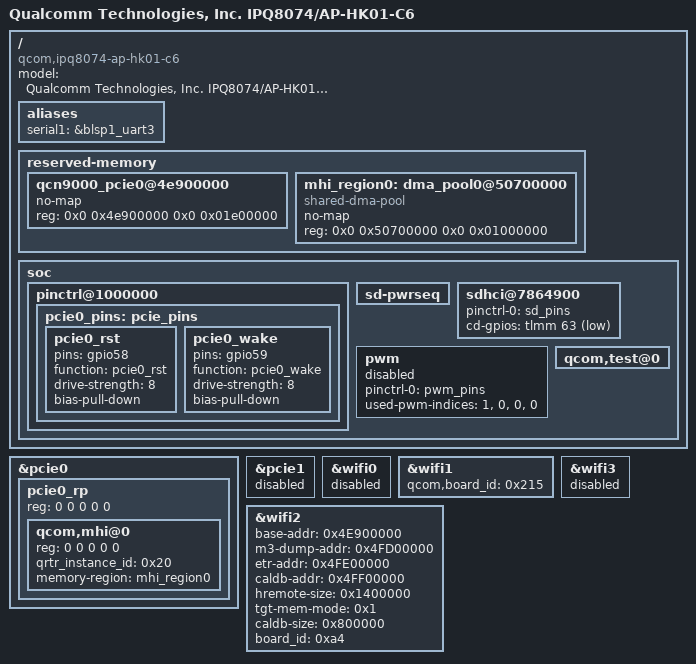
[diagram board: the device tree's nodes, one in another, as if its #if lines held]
// SPDX-License-Identifier: GPL-2.0-only
/dts-v1/;
/* Copyright (c) 2017, 2020, The Linux Foundation. All rights reserved.
 */
#include "ipq8074-hk01.dtsi"

/ {
	model = "Qualcomm Technologies, Inc. IPQ8074/AP-HK01-C6";
	compatible = "qcom,ipq8074-ap-hk01-c6", "qcom,ipq8074-hk01", "qcom,ipq8074";

	aliases {
		serial1 = &blsp1_uart3;
	};

	reserved-memory {
/* No Pine attach in 256M profile */
#if !defined(__IPQ_MEM_PROFILE_256_MB__)
#ifdef __IPQ_MEM_PROFILE_512_MB__
	/*                      512 MB Profile
	 * +========+==============+=========================+
	 * | Region | Start Offset |          Size           |
	 * +--------+--------------+-------------------------+
	 * |  NSS   |  0x40000000  |          16MB           |
	 * +--------+--------------+-------------------------+
	 * |        |              |                         |
	 * | Linux  |  0x41000000  | Depends on total memory |
	 * |        |              |                         |
	 * +--------+--------------+-------------------------+
	 * | TZ APP |  0x4A400000  |           1MB           |
	 * +--------+--------------+-------------------------+
	 * | uboot  |  0x4A600000  |           4MB           |
	 * +--------+--------------+-------------------------+
	 * |  SBL   |  0x4AA00000  |           1MB           |
	 * +--------+--------------+-------------------------+
	 * |  smem  |  0x4AB00000  |           1MB           |
	 * +--------+--------------+-------------------------+
	 * |   TZ   |  0x4AC00000  |           4MB           |
	 * +--------+--------------+-------------------------+
	 * |   Q6   |  0x4B000000  |          55MB           |
	 * +--------+--------------+-------------------------+
	 * |  QDSS  |  0x4E700000  |           1MB           |
	 * +--------+--------------+-------------------------+
	 * | M3 Dump|  0x4E800000  |           1MB           |
	 * +--------+--------------+-------------------------+
	 * |  Pine  |  0x4E900000  |          30MB           |
	 * +--------+--------------+-------------------------+
	 * |  MHI0  |  0x50700000  |          16MB           |
	 * +--------+--------------+-------------------------+
	 * |                                                 |
	 * |      Rest of the memory for Linux               |
	 * |                                                 |
	 * +=================================================+
	 */
		/delete-node/ wifi_dump@4e900000;
		qcn9000_pcie0@4e900000 {
			no-map;
			reg = <0x0 0x4e900000 0x0 0x01e00000>;
		};

		mhi_region0: dma_pool0@50700000 {
			compatible = "shared-dma-pool";
			no-map;
			reg = <0x0 0x50700000 0x0 0x01000000>;
		};
#else
	/*                Default Profile            */
		qcn9000_pcie0@51100000 {
			no-map;
			reg = <0x0 0x51100000 0x0 0x03700000>;
		};

		mhi_region0: dma_pool0@54800000 {
			compatible = "shared-dma-pool";
			no-map;
			reg = <0x0 0x54800000 0x0 0x01800000>;
		};
#endif
#endif
	};

	soc {

		pinctrl@1000000 {
			pcie0_pins: pcie_pins {
				pcie0_rst {
					pins = "gpio58";
					function = "pcie0_rst";
					drive-strength = <8>;
					bias-pull-down;
				};
				pcie0_wake {
					pins = "gpio59";
					function = "pcie0_wake";
					drive-strength = <8>;
					bias-pull-down;
				};
			};

		};

		sd-pwrseq {
			status = "ok";
		};

		sdhci@7864900 {
			pinctrl-0 = <&sd_pins>;
			pinctrl-names = "default";
			cd-gpios = <&tlmm 63 GPIO_ACTIVE_LOW>;
			status = "ok";
		};

		pwm {
			pinctrl-0 = <&pwm_pins>;
			pinctrl-names = "default";
			used-pwm-indices = <1>, <0>, <0>, <0>;
			status = "disabled";
		};

		qcom,test@0 {
			status = "ok";
		};

	};
};

&pcie0 {
        status = "ok";

        pcie0_rp: pcie0_rp {
                reg = <0 0 0 0 0>;

		qcom,mhi@0 {
			reg = <0 0 0 0 0>;
			qrtr_instance_id = <0x20>;
#if !defined(__IPQ_MEM_PROFILE_256_MB__)
			memory-region = <&mhi_region0>;
#endif
		};
	};
};

&pcie1 {
	status = "disabled";
};

&wifi0 {
        status = "disabled";
};

&wifi1 {
	qcom,board_id = <0x215>;
        status = "ok";
};

&wifi2 {
#ifdef __IPQ_MEM_PROFILE_512_MB__
      /* QCN9000 tgt-mem-mode=1 layout - 30MB
       * +=========+==============+=========+
       * |  Region | Start Offset |   Size  |
       * +---------+--------------+---------+
       * | HREMOTE |  0x4E900000  |   20MB  |
       * +---------+--------------+---------+
       * | M3 Dump |  0x4FD00000  |   1MB   |
       * +---------+--------------+---------+
       * |   ETR   |  0x4FE00000  |   1MB   |
       * +---------+--------------+---------+
       * |  Caldb  |  0x4FF00000  |   8MB   |
       * +==================================+
       */
	base-addr = <0x4E900000>;
	m3-dump-addr = <0x4FD00000>;
	etr-addr = <0x4FE00000>;
	caldb-addr = <0x4FF00000>;
	hremote-size = <0x1400000>;
	tgt-mem-mode = <0x1>;
#else
      /* QCN9000 tgt-mem-mode=0 layout - 55MB
       * +=========+==============+=========+
       * |  Region | Start Offset |   Size  |
       * +---------+--------------+---------+
       * | HREMOTE |  0x51100000  |   45MB  |
       * +---------+--------------+---------+
       * | M3 DUMP |  0x53E00000  |   1MB   |
       * +---------+--------------+---------+
       * |   ETR   |  0x53F00000  |   1MB   |
       * +---------+--------------+---------+
       * |  Caldb  |  0x54000000  |   8MB   |
       * +==================================+
       */
        base-addr = <0x51100000>;
	m3-dump-addr = <0x53E00000>;
        etr-addr = <0x53F00000>;
        caldb-addr = <0x54000000>;
	hremote-size = <0x2D00000>;
        tgt-mem-mode = <0x0>;
#endif
        caldb-size = <0x800000>;
	board_id = <0xa4>;
        status = "ok";
};

&wifi3 {
	status = "disabled";
};
